# SN32F420 register map
Vendor: SONiX Technology Co., Ltd.; Series: SN32F420; File version: 1.00
CPU: CM0 r0p0, little endian, no MPU, no FPU, 2 interrupt priority bits
Registers are 32-bit, read-write, reset 0x0 unless marked. A register's access mark holds for its fields unless they carry their own. Offsets are from the block's base; [hi:lo] are bit positions.

## SN_WDT — Watchdog Timer
Base 0x40010000
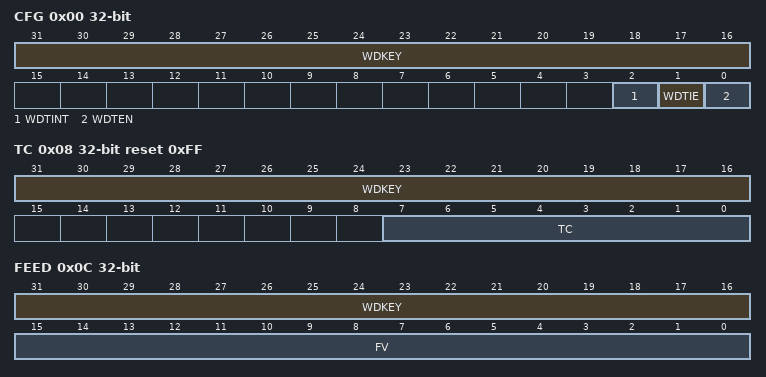
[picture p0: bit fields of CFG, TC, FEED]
0x00 CFG — Offset:0x00 WDT Configuration register
  [31:16] WDKEY wo — WDT register key
  [2] WDTINT — WDT interrupt flag
    0=No (No WDT time-out); 1=WDT time-out (WDT interrupt is triggered if WDTIE=1)
  [1] WDTIE — WDT interrupt enable
    0=Disable (WDT reset when WDT time-out); 1=Enable WDT interrupt
  [0] WDTEN — WDT enable
    0=Disable WDT; 1=Enable WDT
0x08 TC reset 0xFF — Offset:0x08 WDT Timer Constant register
  [31:16] WDKEY wo — WDT register key
  [7:0] TC — Watchdog timer constant reload value
0x0C FEED wo — Offset:0x0C WDT Feed register
  [31:16] WDKEY — WDT register key
  [15:0] FV — Watchdog feed value

## SN_RTC — Real-time Clock
Base 0x40012000
0x00 CTRL — Offset:0x00 RTC Control register
  [0] RTCEN — RTC enable
    0=Disable RTC; 1=Enable RTC
0x08 IE — Offset:0x08 RTC Interrupt Enable register
  [0] SECIE — Second interrupt enable
    0=Disable second interrupt; 1=Enable second interrupt
0x0C RIS ro — Offset:0x0C RTC Raw Interrupt Status register
  [0] SECIF — Second interrupt flag
    0=No (No second interrupt); 1=Met (Second interrupt is triggered when SECIE=1)
0x10 IC wo — Offset:0x10 RTC Interrupt Clear register
  [0] SECIC — Second interrupt flag clear
    0=None (No effect); 1=Clear second interrupt flag
0x14 SECCNTV reset 0x8000 — Offset:0x14 RTC Second Counter Reload Value register
  [19:0] SECCNTV — RTC Second Counter Reload value
0x18 SECCNT ro — Offset:0x18 RTC Second Counter register
  [31:0] SECCNT — RTC Second counter

## SN_OPA — OP Amplifier
Base 0x4002A000
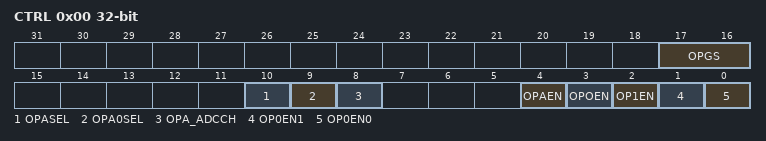
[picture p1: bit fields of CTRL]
0x00 CTRL — Offset:0x0 OPA Control register
  [17:16] OPGS — OPA gain select bit
    0=200K:10K (OPA gain select 200K:10K); 1=190K:20K (OPA gain select 190K:20K); 2=180K:30K (OPA gain select 180K:30K); 3=170K:40K (OPA gain select 170K:40K)
  [10] OPASEL — OPA select bit
    0=OPA0 (OPA is used by OPA0 differential input.); 1=OPA1 (OPA is used by OPA1 differentail input (0P1P/OP1N).)
  [9] OPA0SEL — OPA0 select bit
    0=OPA0P0/OPA0N0 (OPA is used by OPA0P0/OPA0N0); 1=OPA0P1/OPA0N1 (OPA is used by OPA0P1/OPA0N1)
  [8] OPA_ADCCH — OPA0/1 time-division multiplexing OPA function enable bit
    0=Disable (The ADC does not sample OPAO but instead samples the general AIN channel.); 1=Enable (The ADC samples the differential signal of the OPAO.)
  [4] OPAEN — OPA enable bit
    0=Disable OPA. OP0P0/OP0N0/OP0P1/OP0N1/OP1P/OP1N/OPO is GPIO mode.; 1=Enable OPA
  [3] OPOEN — OPA output enable bit
    0=Disable OPA output. OPO/P1.2 is GPIO mode; 1=Enable OPA output. OPO/P1.2 is OP-Amp output pin
  [2] OP1EN — OPA1 enable bit
    0=Disable OPA1. OP1P/P2.2 and OP1N/P2.1 are GPIO mode; 1=Enable OPA1. OP1P/P2.2 and OP1N/P2.1 are OPA1 input pins.
  [1] OP0EN1 — OPA0_1 enable bit
    0=Disable OPA0_1. OP0P1/P1.1 and OP0N1/P1.0 are GPIO mode.; 1=Enable OPA0_1. OP0P1/P1.1 and OP0N1/P1.0 are OPA0 input pins.
  [0] OP0EN0 — OPA0_0 enable bit
    0=Disable OPA0_0. OP0P0/P2.4 and OP0N0/P2.3 are GPIO mode.; 1=Enable OPA0_0. OP0P0/P2.4 and OP0N0/P2.3 are OPA0 input pins.

## SN_PMU — Power Management Unit
Base 0x40032000
0x40 CTRL — Offset:0x40 PMU Control register
  [2:0] MODE — Low Power mode selection
    0=Normal mode; 2=Deep-sleep mode (WFI instruction will make MCU enter Deep-sleep mode); 4=Sleep mode (WFI instruction will make MCU enter Sleep mode)

## SN_CRC — Cyclic Redundancy Check
Base 0x40038000
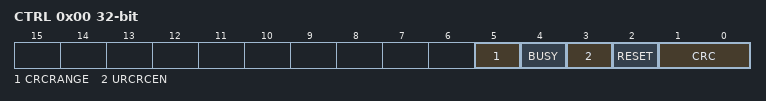
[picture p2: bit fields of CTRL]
0x00 CTRL — Offset:0x0 CRC Control register
  [5] CRCRANGE — CRC calculation range select bit
    0=Range 0 (All User ROM, except the last page (0x00000000~0x00007DFF)); 1=Range 1 (All User ROM, except the last 2 pages (0x00000000~0x00007BFF))
  [4] BUSY ro — CRC calculation busy flag
    0=Idle/Finish (CRC calculation idle/finished); 1=Busy (CRC calculation is in process)
  [3] URCRCEN — CRC calculation for the User ROM enable bit
    0=Stop/Finish CRC calculation; 1=Enable (Start CRC calculation for the User ROM)
  [2] RESET — CRC Reset bit
    0=No (No effect); 1=Reset CRC circuit
  [1:0] CRC — CRC Polynomial
    0=CRC-16-CCITT (CRC-16-CCITT Polynomial); 1=CRC-16 (CRC-16 Polynomial); 2=CRC-32 (CRC-32 Polynomial)
0x04 DATA — Offset:0x4 CRC Data register
  [31:0] DATA — CRC Data
